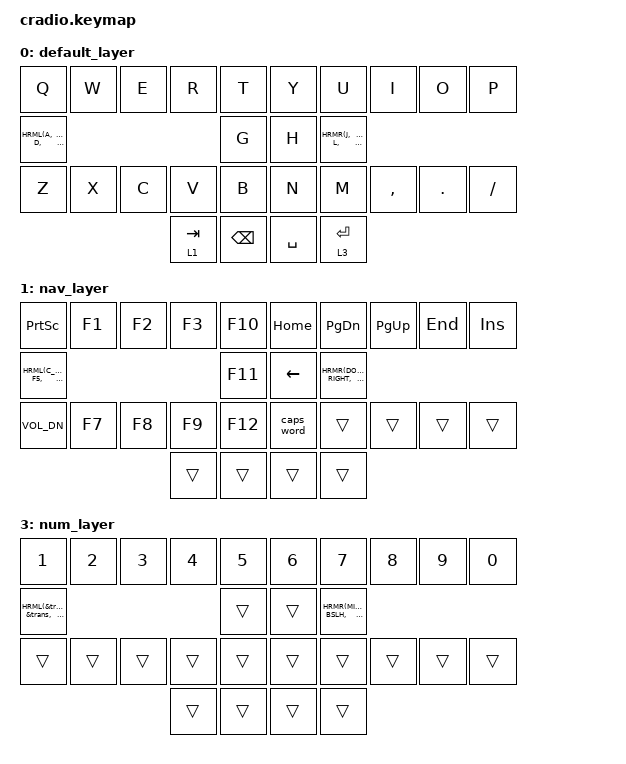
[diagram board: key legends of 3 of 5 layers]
// Copyright (c) 2022 The ZMK Contributors
// SPDX-License-Identifier: MIT

#include <behaviors.dtsi>
#include <dt-bindings/zmk/keys.h>
#include <dt-bindings/zmk/bt.h>

// Home row mods macro
#define HRML(k1,k2,k3,k4) &ht LGUI k1  &ht LALT k2  &ht LCTRL k3  &ht LSHFT k4
#define HRMR(k1,k2,k3,k4) &ht RSHFT k1  &ht RCTRL k2  &ht RALT k3  &ht RGUI k4

/*
╭─────┬─────┬─────┬─────┬─────╮   ╭─────┬─────┬─────┬─────┬─────╮
│  0  │  1  │  2  │  3  │  4  │   │  5  │  6  │  7  │  8  │  9  │
├─────┼─────┼─────┼─────┼─────┤   ├─────┼─────┼─────┼─────┼─────┤
│ 10  │ 11  │ 12  │ 13  │ 14  │   │ 15  │ 16  │ 17  │ 18  │ 19  │
├─────┼─────┼─────┼─────┼─────┤   ├─────┼─────┼─────┼─────┼─────┤
│ 20  │ 21  │ 22  │ 23  │ 24  │   │ 25  │ 26  │ 27  │ 28  │ 29  │
╰─────┴─────┴─────┼─────┼─────┤   ├─────┼─────┼─────┴─────┴─────╯
                   │ 30  │ 31  │   │ 32  │ 33  │
                   ╰─────┴─────╯   ╰─────┴─────╯
*/

/ {
    behaviors {
        ht: hold_tap {
            compatible = "zmk,behavior-hold-tap";
            #binding-cells = <2>;
            flavor = "balanced";
            tapping-term-ms = <280>;
            quick-tap-ms = <175>;
            require-prior-idle-ms = <150>;
            bindings = <&kp>, <&kp>;
        };
    };

    combos {
        compatible = "zmk,combos";
        combo_esc {
            timeout-ms = <50>;
            key-positions = <1 2>;
            bindings = <&kp ESC>;
        };
        combo_sym { 
            timeout-ms = <75>;
            key-positions = <31 32>;
            bindings = <&mo 2>;
        };
    };

    conditional_layers {
        compatible = "zmk,conditional-layers";
        feat_layer {
            if-layers = <1 3>;
            then-layer = <4>;
        };
    };

    keymap {
        compatible = "zmk,keymap";
        default_layer {
            bindings = <
        //╭──────────┬──────────┬──────────┬──────────┬──────────╮   ╭──────────┬──────────┬──────────┬──────────┬──────────╮
        //│  Q       │  W       │  E       │  R       │  T       │   │  Y       │  U       │  I       │  O       │  P       │
            &kp Q      &kp W      &kp E      &kp R      &kp T          &kp Y      &kp U      &kp I      &kp O      &kp P
        //├──────────┼──────────┼──────────┼──────────┼──────────┤   ├──────────┼──────────┼──────────┼──────────┼──────────┤
        //│  A       │  S       │  D       │  F       │  G       │   │  H       │  J       │  K       │  L       │ ' "      │
            HRML(A,        S,         D,         F)     &kp G          &kp H      HRMR(J,        K,         L,        SQT)
        //├──────────┼──────────┼──────────┼──────────┼──────────┤   ├──────────┼──────────┼──────────┼──────────┼──────────┤
        //│  Z       │  X       │  C       │  V       │  B       │   │  N       │  M       │ , <      │ . >      │ / ?      │
            &kp Z      &kp X      &kp C      &kp V      &kp B          &kp N      &kp M      &kp COMMA  &kp DOT    &kp FSLH
        //╰──────────┴──────────┴──────────┼──────────┼──────────┤   ├──────────┼──────────┼──────────┴──────────┴──────────╯
                                            &lt 1 TAB   &kp BSPC       &kp SPACE  &lt 3 ENTER
        //                                 ╰──────────┴──────────╯   ╰──────────┴──────────╯
            >;
        };

        nav_layer {
            bindings = <
        //╭──────────┬──────────┬──────────┬──────────┬──────────╮   ╭──────────┬──────────┬──────────┬──────────┬──────────╮
        //│  PrtScrn │  F1      │  F2      │  F3      │    F10   │   │ HOME     │ PAGE DN  │ PAGE UP  │ END      │ INSERT   │
            &kp PSCRN  &kp F1     &kp F2     &kp F3     &kp F10        &kp HOME   &kp PG_DN  &kp PG_UP  &kp END    &kp INS
        //├──────────┼──────────┼──────────┼──────────┼──────────┤   ├──────────┼──────────┼──────────┼──────────┼──────────┤
        //│ Vol Up   │  F4      │  F5      │  F6      │  F11     │   │ LEFT     │ DOWN     │   UP     │  RIGHT   │   CAPS   │
          HRML(C_VOL_UP,  F4,      F5,        F6)      &kp F11         &kp LEFT  HRMR(DOWN,    UP,       RIGHT,      CAPS)
        //├──────────┼──────────┼──────────┼──────────┼──────────┤   ├──────────┼──────────┼──────────┼──────────┼──────────┤
        //│ Vol Down │  F7      │  F8      │  F9      │  F12     │   │          │          │          │          │          │
         &kp C_VOL_DN  &kp F7     &kp F8     &kp F9     &kp F12       &caps_word    &trans     &trans     &trans     &trans
        //╰──────────┴──────────┴──────────┼──────────┼──────────┤   ├──────────┼──────────┼──────────┴──────────┴──────────╯
                                             &trans     &trans        &trans     &trans
        //                                 ╰──────────┴──────────╯   ╰──────────┴──────────╯
            >;
        };

        sym_layer {
            bindings = <
        //╭──────────┬──────────┬──────────┬──────────┬──────────╮   ╭──────────┬──────────┬──────────┬──────────┬──────────╮
        //│     `    │  ~       │  #       │  &       │    |     │   │  ^       │  {       │  }       │  [       │  ]       │
            &kp GRAVE  &kp TILDE   &kp HASH  &kp AMPS   &kp PIPE      &kp CARET  &kp LBRC   &kp RBRC   &kp LBKT   &kp RBKT
        //├──────────┼──────────┼──────────┼──────────┼──────────┤   ├──────────┼──────────┼──────────┼──────────┼──────────┤
        //│  !       │   _      │  :       │  =       │    $     │   │   @      │  (       │   )      │  _       │  ;       │
            &kp EXCL   &kp UNDER   &kp COLON &kp EQUAL   &kp DLLR       &kp AT   &kp LPAR   &kp RPAR   &kp UNDER   &kp SEMI
        //├──────────┼──────────┼──────────┼──────────┼──────────┤   ├──────────┼──────────┼──────────┼──────────┼──────────┤
        //│    %     │    ?     │    *     │    +     │    \     │   │   /      │    -     │   <      │    >     │    "     │
            &kp PRCNT  &kp QMARK   &kp STAR  &kp PLUS   &kp BSLH        &kp FSLH  &kp MINUS   &kp LT    &kp GT     &kp DQT
        //╰──────────┴──────────┴──────────┼──────────┼──────────┤   ├──────────┼──────────┼──────────┴──────────┴──────────╯
                                             &trans     &trans         &trans     &trans
        //                                 ╰──────────┴──────────╯   ╰──────────┴──────────╯
            >;
        };


        num_layer {
            bindings = <
        //╭──────────┬──────────┬──────────┬──────────┬──────────╮   ╭──────────┬──────────┬──────────┬──────────┬──────────╮
        //│    1/!   │   2/@    │    3/#   │   4/$    │  5/%     │   │  6/^     │  7/&     │  8/*     │  9/(     │  0/)     │
            &kp N1     &kp N2     &kp N3     &kp N4    &kp N5         &kp N6     &kp N7     &kp N8     &kp N9     &kp N0
        //├──────────┼──────────┼──────────┼──────────┼──────────┤   ├──────────┼──────────┼──────────┼──────────┼──────────┤
        //│          │          │          │          │          │   │          │  -/_     │  =/+     │  \/|     │  `/~     │
          HRML(&trans,  &trans,   &trans,    &trans)     &trans        &trans    HRMR(MINUS,    EQUAL,   BSLH,      GRAVE)
        //├──────────┼──────────┼──────────┼──────────┼──────────┤   ├──────────┼──────────┼──────────┼──────────┼──────────┤
        //│          │          │          │          │          │   │          │          │          │          │          │
            &trans     &trans     &trans     &trans     &trans         &trans    &trans    &trans    &trans    &trans
        //╰──────────┴──────────┴──────────┼──────────┼──────────┤   ├──────────┼──────────┼──────────┴──────────┴──────────╯
                                             &trans     &trans         &trans     &trans
        //                                 ╰──────────┴──────────╯   ╰──────────┴──────────╯
            >;
        };

        feat_layer {
            bindings = <
        //╭──────────┬──────────┬──────────┬──────────┬──────────╮   ╭──────────┬──────────┬──────────┬──────────┬──────────╮
        //│ RESET    │          │          │          │PROFILE 0 │   │          │          │          │          │  RESET   │
           &sys_reset  &trans     &trans     &trans    &bt BT_SEL 0    &trans     &trans     &trans     &trans    &sys_reset
        //├──────────┼──────────┼──────────┼──────────┼──────────┤   ├──────────┼──────────┼──────────┼──────────┼──────────┤
        //│BOOTLOADER│          │          │CLEARALLBT│PROFILE 1 │   │          │          │          │          │BOOTLOADER│
          &bootloader  &trans     &trans  &bt BT_CLR_ALL &bt BT_SEL 1    &trans     &trans     &trans     &trans    &bootloader
        //├──────────┼──────────┼──────────┼──────────┼──────────┤   ├──────────┼──────────┼──────────┼──────────┼──────────┤
        //│ZMK UNLOCK│          │          │ CLEAR BT │PROFILE 2 │   │          │          │          │          │ZMK UNLOCK|
        &studio_unlock &trans     &trans    &bt BT_CLR &bt BT_SEL 2    &trans     &trans     &trans     &trans    &studio_unlock
        //╰──────────┴──────────┴──────────┼──────────┼──────────┤   ├──────────┼──────────┼──────────┴──────────┴──────────╯
                                             &trans     &trans         &trans     &trans
        //                                 ╰──────────┴──────────╯   ╰──────────┴──────────╯
            >;
        };
    };
};
